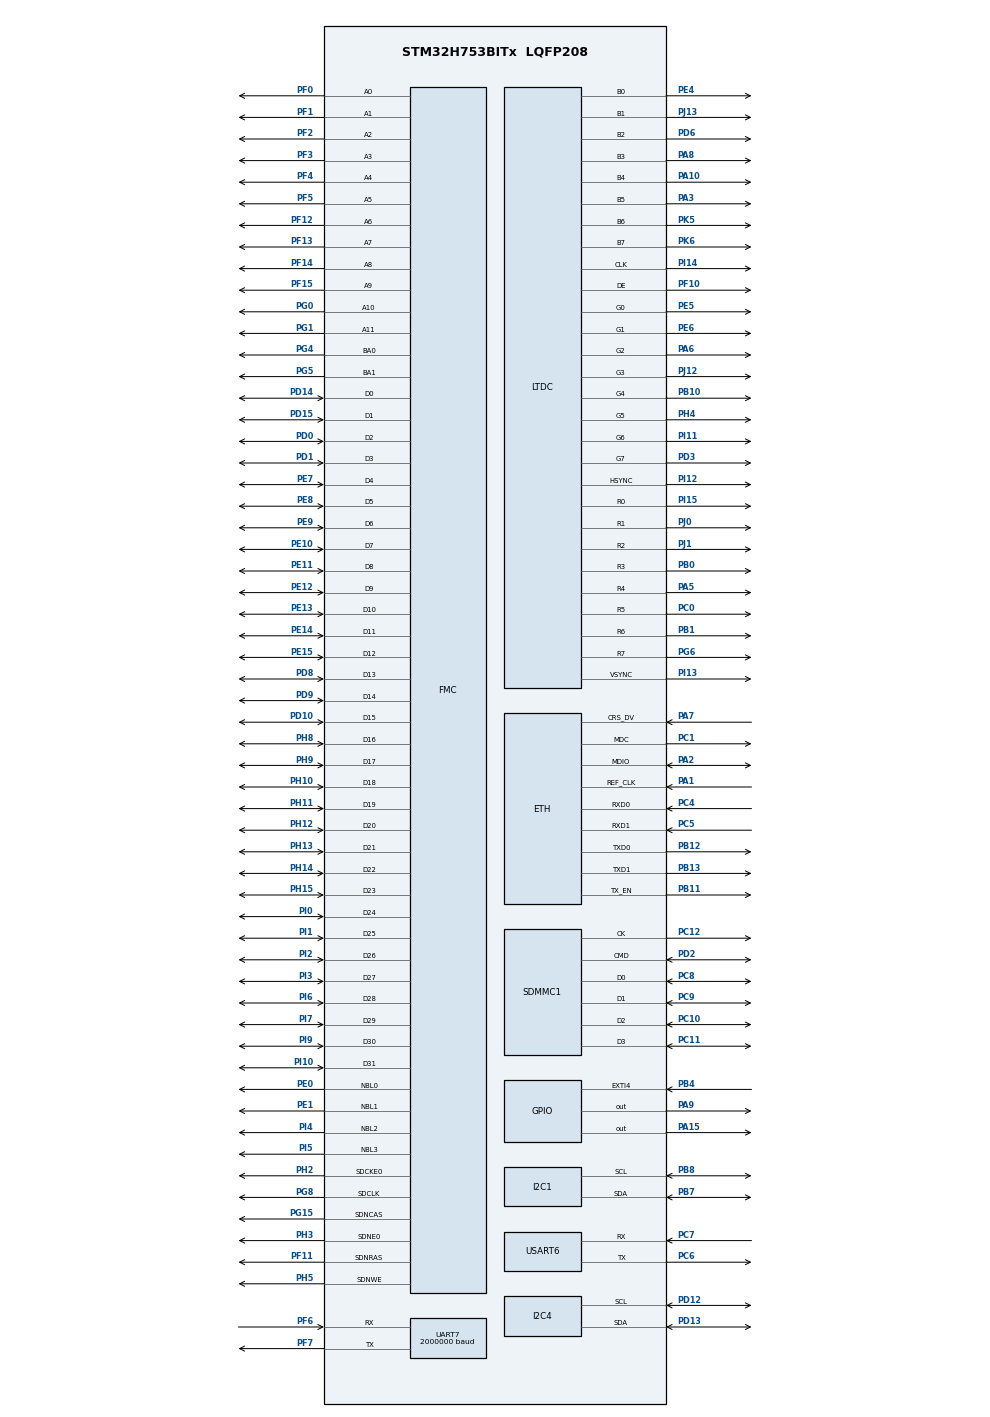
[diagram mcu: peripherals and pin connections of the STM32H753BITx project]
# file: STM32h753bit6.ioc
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CORTEX_M7.AccessPermission-Cortex_Memory_Protection_Unit_Region5_Settings=MPU_REGION_FULL_ACCESS
CORTEX_M7.AccessPermission-Cortex_Memory_Protection_Unit_Region6_Settings=MPU_REGION_FULL_ACCESS
CORTEX_M7.AccessPermission_S-Cortex_Memory_Protection_Unit_Region1_Settings_S=MPU_REGION_FULL_ACCESS
CORTEX_M7.AccessPermission_S-Cortex_Memory_Protection_Unit_Region2_Settings_S=MPU_REGION_FULL_ACCESS
CORTEX_M7.AccessPermission_S-Cortex_Memory_Protection_Unit_Region3_Settings_S=MPU_REGION_FULL_ACCESS
CORTEX_M7.AccessPermission_S-Cortex_Memory_Protection_Unit_Region4_Settings_S=MPU_REGION_FULL_ACCESS
CORTEX_M7.BaseAddress-Cortex_Memory_Protection_Unit_Region5_Settings=0x30040000
CORTEX_M7.BaseAddress-Cortex_Memory_Protection_Unit_Region6_Settings=0x30040000
CORTEX_M7.BaseAddress_S-Cortex_Memory_Protection_Unit_Region1_Settings_S=0x24000000
CORTEX_M7.BaseAddress_S-Cortex_Memory_Protection_Unit_Region2_Settings_S=0x30000000
CORTEX_M7.BaseAddress_S-Cortex_Memory_Protection_Unit_Region3_Settings_S=0x38000000
CORTEX_M7.BaseAddress_S-Cortex_Memory_Protection_Unit_Region4_Settings_S=0x60000000
CORTEX_M7.CPU_DCache=Enabled
CORTEX_M7.CPU_ICache=Enabled
CORTEX_M7.DisableExec-Cortex_Memory_Protection_Unit_Region5_Settings=MPU_INSTRUCTION_ACCESS_DISABLE
CORTEX_M7.DisableExec-Cortex_Memory_Protection_Unit_Region6_Settings=MPU_INSTRUCTION_ACCESS_DISABLE
CORTEX_M7.DisableExec_S-Cortex_Memory_Protection_Unit_Region1_Settings_S=MPU_INSTRUCTION_ACCESS_DISABLE
CORTEX_M7.DisableExec_S-Cortex_Memory_Protection_Unit_Region2_Settings_S=MPU_INSTRUCTION_ACCESS_DISABLE
CORTEX_M7.DisableExec_S-Cortex_Memory_Protection_Unit_Region3_Settings_S=MPU_INSTRUCTION_ACCESS_DISABLE
CORTEX_M7.DisableExec_S-Cortex_Memory_Protection_Unit_Region4_Settings_S=MPU_INSTRUCTION_ACCESS_DISABLE
CORTEX_M7.Enable-Cortex_Memory_Protection_Unit_Region5_Settings=MPU_REGION_ENABLE
CORTEX_M7.Enable-Cortex_Memory_Protection_Unit_Region6_Settings=MPU_REGION_ENABLE
CORTEX_M7.Enable_S-Cortex_Memory_Protection_Unit_Region1_Settings_S=MPU_REGION_ENABLE
CORTEX_M7.Enable_S-Cortex_Memory_Protection_Unit_Region2_Settings_S=MPU_REGION_ENABLE
CORTEX_M7.Enable_S-Cortex_Memory_Protection_Unit_Region3_Settings_S=MPU_REGION_ENABLE
CORTEX_M7.Enable_S-Cortex_Memory_Protection_Unit_Region4_Settings_S=MPU_REGION_ENABLE
CORTEX_M7.IsBufferable-Cortex_Memory_Protection_Unit_Region5_Settings=MPU_ACCESS_NOT_BUFFERABLE
CORTEX_M7.IsBufferable-Cortex_Memory_Protection_Unit_Region6_Settings=MPU_ACCESS_BUFFERABLE
CORTEX_M7.IsBufferable_S-Cortex_Memory_Protection_Unit_Region1_Settings_S=MPU_ACCESS_BUFFERABLE
CORTEX_M7.IsBufferable_S-Cortex_Memory_Protection_Unit_Region2_Settings_S=MPU_ACCESS_BUFFERABLE
CORTEX_M7.IsBufferable_S-Cortex_Memory_Protection_Unit_Region3_Settings_S=MPU_ACCESS_BUFFERABLE
CORTEX_M7.IsBufferable_S-Cortex_Memory_Protection_Unit_Region4_Settings_S=MPU_ACCESS_BUFFERABLE
CORTEX_M7.IsCacheable-Cortex_Memory_Protection_Unit_Region5_Settings=MPU_ACCESS_NOT_CACHEABLE
CORTEX_M7.IsCacheable-Cortex_Memory_Protection_Unit_Region6_Settings=MPU_ACCESS_NOT_CACHEABLE
CORTEX_M7.IsCacheable_S-Cortex_Memory_Protection_Unit_Region1_Settings_S=MPU_ACCESS_CACHEABLE
CORTEX_M7.IsCacheable_S-Cortex_Memory_Protection_Unit_Region2_Settings_S=MPU_ACCESS_CACHEABLE
CORTEX_M7.IsCacheable_S-Cortex_Memory_Protection_Unit_Region3_Settings_S=MPU_ACCESS_CACHEABLE
CORTEX_M7.IsCacheable_S-Cortex_Memory_Protection_Unit_Region4_Settings_S=MPU_ACCESS_CACHEABLE
CORTEX_M7.IsShareable-Cortex_Memory_Protection_Unit_Region6_Settings=MPU_ACCESS_SHAREABLE
CORTEX_M7.Size-Cortex_Memory_Protection_Unit_Region5_Settings=MPU_REGION_SIZE_32KB
CORTEX_M7.Size-Cortex_Memory_Protection_Unit_Region6_Settings=MPU_REGION_SIZE_256B
CORTEX_M7.Size_S-Cortex_Memory_Protection_Unit_Region1_Settings_S=MPU_REGION_SIZE_512KB
CORTEX_M7.Size_S-Cortex_Memory_Protection_Unit_Region2_Settings_S=MPU_REGION_SIZE_256KB
CORTEX_M7.Size_S-Cortex_Memory_Protection_Unit_Region3_Settings_S=MPU_REGION_SIZE_64KB
CORTEX_M7.Size_S-Cortex_Memory_Protection_Unit_Region4_Settings_S=MPU_REGION_SIZE_16MB
CORTEX_M7.TypeExtField-Cortex_Memory_Protection_Unit_Region5_Settings=MPU_TEX_LEVEL1
CORTEX_M7.TypeExtField_S-Cortex_Memory_Protection_Unit_Region1_Settings_S=MPU_TEX_LEVEL1
CORTEX_M7.TypeExtField_S-Cortex_Memory_Protection_Unit_Region2_Settings_S=MPU_TEX_LEVEL1
CORTEX_M7.TypeExtField_S-Cortex_Memory_Protection_Unit_Region3_Settings_S=MPU_TEX_LEVEL1
CORTEX_M7.TypeExtField_S-Cortex_Memory_Protection_Unit_Region4_Settings_S=MPU_TEX_LEVEL1
CORTEX_M7.default_mode_Activation=1
Dma.Request0=USART6_RX
Dma.Request1=USART6_TX
Dma.Request2=UART7_RX
Dma.Request3=UART7_TX
Dma.UART7_RX.2.Direction=DMA_PERIPH_TO_MEMORY
Dma.UART7_RX.2.EventEnable=DISABLE
Dma.UART7_RX.2.FIFOMode=DMA_FIFOMODE_DISABLE
Dma.UART7_RX.2.Instance=DMA1_Stream2
Dma.UART7_RX.2.MemDataAlignment=DMA_MDATAALIGN_BYTE
Dma.UART7_RX.2.MemInc=DMA_MINC_ENABLE
Dma.UART7_RX.2.Mode=DMA_NORMAL
Dma.UART7_RX.2.PeriphDataAlignment=DMA_PDATAALIGN_BYTE
Dma.UART7_RX.2.PeriphInc=DMA_PINC_DISABLE
Dma.UART7_RX.2.Polarity=HAL_DMAMUX_REQ_GEN_RISING
Dma.UART7_RX.2.Priority=DMA_PRIORITY_LOW
Dma.UART7_RX.2.RequestNumber=1
Dma.UART7_RX.2.SignalID=NONE
Dma.UART7_RX.2.SyncEnable=DISABLE
Dma.UART7_RX.2.SyncPolarity=HAL_DMAMUX_SYNC_NO_EVENT
Dma.UART7_RX.2.SyncRequestNumber=1
Dma.UART7_RX.2.SyncSignalID=NONE
Dma.UART7_TX.3.Direction=DMA_MEMORY_TO_PERIPH
Dma.UART7_TX.3.EventEnable=DISABLE
Dma.UART7_TX.3.FIFOMode=DMA_FIFOMODE_DISABLE
Dma.UART7_TX.3.Instance=DMA1_Stream3
Dma.UART7_TX.3.MemDataAlignment=DMA_MDATAALIGN_BYTE
Dma.UART7_TX.3.MemInc=DMA_MINC_ENABLE
Dma.UART7_TX.3.Mode=DMA_NORMAL
Dma.UART7_TX.3.PeriphDataAlignment=DMA_PDATAALIGN_BYTE
Dma.UART7_TX.3.PeriphInc=DMA_PINC_DISABLE
Dma.UART7_TX.3.Polarity=HAL_DMAMUX_REQ_GEN_RISING
Dma.UART7_TX.3.Priority=DMA_PRIORITY_LOW
Dma.UART7_TX.3.RequestNumber=1
Dma.UART7_TX.3.SignalID=NONE
Dma.UART7_TX.3.SyncEnable=DISABLE
Dma.UART7_TX.3.SyncPolarity=HAL_DMAMUX_SYNC_NO_EVENT
Dma.UART7_TX.3.SyncRequestNumber=1
Dma.UART7_TX.3.SyncSignalID=NONE
Dma.USART6_RX.0.Direction=DMA_PERIPH_TO_MEMORY
Dma.USART6_RX.0.EventEnable=DISABLE
Dma.USART6_RX.0.FIFOMode=DMA_FIFOMODE_DISABLE
Dma.USART6_RX.0.Instance=DMA1_Stream0
Dma.USART6_RX.0.MemDataAlignment=DMA_MDATAALIGN_BYTE
Dma.USART6_RX.0.MemInc=DMA_MINC_ENABLE
Dma.USART6_RX.0.Mode=DMA_CIRCULAR
Dma.USART6_RX.0.PeriphDataAlignment=DMA_PDATAALIGN_BYTE
Dma.USART6_RX.0.PeriphInc=DMA_PINC_DISABLE
Dma.USART6_RX.0.Polarity=HAL_DMAMUX_REQ_GEN_RISING
Dma.USART6_RX.0.Priority=DMA_PRIORITY_LOW
Dma.USART6_RX.0.RequestNumber=1
Dma.USART6_RX.0.SignalID=NONE
Dma.USART6_RX.0.SyncEnable=DISABLE
Dma.USART6_RX.0.SyncPolarity=HAL_DMAMUX_SYNC_NO_EVENT
Dma.USART6_RX.0.SyncRequestNumber=1
Dma.USART6_RX.0.SyncSignalID=NONE
Dma.USART6_TX.1.Direction=DMA_MEMORY_TO_PERIPH
Dma.USART6_TX.1.EventEnable=DISABLE
Dma.USART6_TX.1.FIFOMode=DMA_FIFOMODE_DISABLE
Dma.USART6_TX.1.Instance=DMA1_Stream1
Dma.USART6_TX.1.MemDataAlignment=DMA_MDATAALIGN_BYTE
Dma.USART6_TX.1.MemInc=DMA_MINC_ENABLE
Dma.USART6_TX.1.Mode=DMA_NORMAL
Dma.USART6_TX.1.PeriphDataAlignment=DMA_PDATAALIGN_BYTE
Dma.USART6_TX.1.PeriphInc=DMA_PINC_DISABLE
Dma.USART6_TX.1.Polarity=HAL_DMAMUX_REQ_GEN_RISING
Dma.USART6_TX.1.Priority=DMA_PRIORITY_LOW
Dma.USART6_TX.1.RequestNumber=1
Dma.USART6_TX.1.SignalID=NONE
Dma.USART6_TX.1.SyncEnable=DISABLE
Dma.USART6_TX.1.SyncPolarity=HAL_DMAMUX_SYNC_NO_EVENT
Dma.USART6_TX.1.SyncRequestNumber=1
Dma.USART6_TX.1.SyncSignalID=NONE
ETH.MediaInterface=HAL_ETH_RMII_MODE
ETH.RxBuffAddress=0x30040200
ETH.RxBuffLen=1536
FATFS.USE_DMA_CODE_SD=1
FATFS._CODE_PAGE=775
FATFS._FS_LOCK=10
FATFS._FS_RPATH=2
FATFS._FS_TIMEOUT=2000
FATFS._USE_CHMOD=1
FATFS._USE_EXPAND=1
FATFS._USE_FIND=1
FATFS._USE_LFN=3
FMC.BankMapConfig=FMC_SWAPBMAP_SDRAM_SRAM
FMC.CASLatency1=FMC_SDRAM_CAS_LATENCY_2
FMC.ExitSelfRefreshDelay1=7
FMC.LoadToActiveDelay1=2
FMC.RCDDelay1=2
FMC.RPDelay1=2
FMC.RPDelay2=2
FMC.ReadBurst1=FMC_SDRAM_RBURST_ENABLE
FMC.ReadBurst2=FMC_SDRAM_RBURST_ENABLE
FMC.ReadPipeDelay1=FMC_SDRAM_RPIPE_DELAY_1
FMC.ReadPipeDelay2=FMC_SDRAM_RPIPE_DELAY_1
FMC.RowCycleDelay1=7
FMC.RowCycleDelay2=7
FMC.SDClockPeriod1=FMC_SDRAM_CLOCK_PERIOD_2
FMC.SDClockPeriod2=FMC_SDRAM_CLOCK_PERIOD_2
FMC.SelfRefreshTime1=5
FMC.WriteRecoveryTime1=3
FREERTOS.INCLUDE_vTaskDelayUntil=1
FREERTOS.INCLUDE_xEventGroupSetBitFromISR=1
FREERTOS.INCLUDE_xTimerPendFunctionCall=1
FREERTOS.Tasks01=defaultTask,0,2048,StartDefaultTask,Default,NULL,Dynamic,NULL,NULL
FREERTOS.configENABLE_FPU=1
FREERTOS.configMAX_PRIORITIES=9
FREERTOS.configMINIMAL_STACK_SIZE=256
FREERTOS.configTOTAL_HEAP_SIZE=131072
FREERTOS.configUSE_IDLE_HOOK=1
FREERTOS.configUSE_TICK_HOOK=1
FREERTOS.configUSE_TIMERS=1
FREERTOS.configUSE_TRACE_FACILITY=1
I2C1.Timing=0x307075B1
I2C4.Timing=0x307075B1
LTDC.ActiveW=800
LTDC.Alpha0_L0=255
LTDC.Alpha_L0=255
LTDC.BlendingFactor1_L0=LTDC_BLENDING_FACTOR1_PAxCA
LTDC.BlendingFactor2_L0=LTDC_BLENDING_FACTOR2_PAxCA
LTDC.FBStartAdress_L0=0x60000000
LTDC.HSync=39
LTDC.ImageHeight_L0=480
LTDC.ImageWidth_L0=800
LTDC.Layers=0
LTDC.PixelFormat_L0=LTDC_PIXEL_FORMAT_RGB888
LTDC.VSync=3
LTDC.WindowX1_L0=800
LTDC.WindowY1_L0=480
LWIP.BSP.number=1
LWIP.DEFAULT_THREAD_STACKSIZE=8000
LWIP.GATEWAY_ADDRESS=192.168.001.001
LWIP.IP_ADDRESS=192.168.001.040
LWIP.LWIP_DHCP=0
LWIP.LWIP_DNS=1
LWIP.LWIP_RAM_HEAP_POINTER=0x30044000
LWIP.LWIP_SMTP=1
LWIP.LWIP_SNTP=1
LWIP.LWIP_TCPIP_CORE_LOCKING=1
LWIP.MEMP_NUM_NETBUF=32
LWIP.MEMP_NUM_NETCONN=32
LWIP.MEMP_NUM_PBUF=32
LWIP.MEMP_NUM_SYS_TIMEOUT=32
LWIP.MEMP_NUM_TCP_SEG=32
LWIP.MEM_ALIGNMENT=4
LWIP.MEM_SIZE=16360
LWIP.NETMASK_ADDRESS=255.255.255.000
LWIP.PBUF_POOL_BUFSIZE=1526
LWIP.PBUF_POOL_SIZE=24
LWIP.SLIPIF_THREAD_STACKSIZE=16000
LWIP.SO_REUSE=1
LWIP.TCP_MSS=1460
LWIP.TCP_SNDLOWAT=2919
LWIP.TCP_SND_BUF=2920
LWIP.TCP_WND_UPDATE_THRESHOLD=1460
LWIP.Version=v2.1.2_Cube
LWIP0.BSP.STBoard=false
LWIP0.BSP.api=BSP_COMPONENT_DRIVER
LWIP0.BSP.component=LAN8742
LWIP0.BSP.instance=LAN8742
LWIP0.BSP.name=Driver_PHY
LWIP0.BSP.semaphore=S_LAN8742
LWIP0.BSP.solution=LAN8742
MBEDTLS.MBEDTLS_KEY_EXCHANGE_ECDH_RSA_ENABLED=1
MBEDTLS.MBEDTLS_MEMORY_BUFFER_ALLOC_C=1
MBEDTLS.MBEDTLS_PK_RSA_ALT_SUPPORT=0
MBEDTLS.MBEDTLS_PLATFORM_MEMORY=1
MBEDTLS.MBEDTLS_RSA_C=1
MBEDTLS.MBEDTLS_THREADING_C=1
MBEDTLS.MBEDTLS_X509_RSASSA_PSS_SUPPORT=1
Mcu.Family=STM32H7
Mcu.Name=STM32H753BITx
Mcu.Package=LQFP208
Mdma.MDMA_Channel0.Request0=SDMMC1_END_DATA
Mdma.MDMA_Channel0.RequestsNb=1
Mdma.MDMA_Channel0.SDMMC1_END_DATA.0.BlockCount=0
Mdma.MDMA_Channel0.SDMMC1_END_DATA.0.BlockDataLength=0
Mdma.MDMA_Channel0.SDMMC1_END_DATA.0.BufferTransferLength=16
Mdma.MDMA_Channel0.SDMMC1_END_DATA.0.CircularMode=MDMA_LINEAR_LIST
Mdma.MDMA_Channel0.SDMMC1_END_DATA.0.DataAlignment=MDMA_DATAALIGN_PACKENABLE
Mdma.MDMA_Channel0.SDMMC1_END_DATA.0.DestBlockAddressOffset=0
Mdma.MDMA_Channel0.SDMMC1_END_DATA.0.DestBurst=MDMA_DEST_BURST_SINGLE
Mdma.MDMA_Channel0.SDMMC1_END_DATA.0.DestDataSize=MDMA_DEST_DATASIZE_BYTE
Mdma.MDMA_Channel0.SDMMC1_END_DATA.0.DestinationInc=MDMA_DEST_INC_BYTE
Mdma.MDMA_Channel0.SDMMC1_END_DATA.0.DstAddress=0
Mdma.MDMA_Channel0.SDMMC1_END_DATA.0.Endianness=MDMA_LITTLE_ENDIANNESS_PRESERVE
Mdma.MDMA_Channel0.SDMMC1_END_DATA.0.Instance=MDMA_Channel0
Mdma.MDMA_Channel0.SDMMC1_END_DATA.0.MaskAddress=0
Mdma.MDMA_Channel0.SDMMC1_END_DATA.0.MaskData=0
Mdma.MDMA_Channel0.SDMMC1_END_DATA.0.Priority=MDMA_PRIORITY_LOW
Mdma.MDMA_Channel0.SDMMC1_END_DATA.0.Rank=First
Mdma.MDMA_Channel0.SDMMC1_END_DATA.0.SourceBlockAddressOffset=0
Mdma.MDMA_Channel0.SDMMC1_END_DATA.0.SourceBurst=MDMA_SOURCE_BURST_SINGLE
Mdma.MDMA_Channel0.SDMMC1_END_DATA.0.SourceDataSize=MDMA_SRC_DATASIZE_BYTE
Mdma.MDMA_Channel0.SDMMC1_END_DATA.0.SourceInc=MDMA_SRC_INC_BYTE
Mdma.MDMA_Channel0.SDMMC1_END_DATA.0.SrcAddress=0
Mdma.MDMA_Channel0.SDMMC1_END_DATA.0.TransferTriggerMode=MDMA_BUFFER_TRANSFER
Mdma.RequestSet0=MDMA_Channel0
Mdma.RequestSetsNb=1
NVIC.DMA1_Stream0_IRQn=true\:5\:0\:false\:false\:true\:true\:false\:true\:true
NVIC.DMA1_Stream1_IRQn=true\:5\:0\:false\:false\:true\:true\:false\:true\:true
NVIC.DMA1_Stream2_IRQn=true\:5\:0\:false\:false\:true\:true\:false\:true\:true
NVIC.DMA1_Stream3_IRQn=true\:5\:0\:false\:false\:true\:true\:false\:true\:true
NVIC.ETH_IRQn=true\:5\:0\:false\:false\:true\:true\:true\:true\:true
NVIC.EXTI4_IRQn=true\:5\:0\:false\:false\:true\:true\:true\:true\:true
NVIC.MDMA_IRQn=true\:5\:0\:false\:false\:true\:true\:false\:true\:true
NVIC.PriorityGroup=NVIC_PRIORITYGROUP_4
NVIC.SDMMC1_IRQn=true\:5\:0\:false\:false\:true\:true\:true\:true\:true
NVIC.TIM8_TRG_COM_TIM14_IRQn=true\:15\:0\:false\:false\:true\:false\:false\:true\:true
NVIC.TimeBase=TIM8_TRG_COM_TIM14_IRQn
NVIC.TimeBaseIP=TIM14
NVIC.UART7_IRQn=true\:5\:0\:false\:false\:true\:true\:true\:true\:true
NVIC.USART6_IRQn=true\:5\:0\:false\:false\:true\:true\:true\:true\:true
PA1.Mode=RMII
PA1.Signal=ETH_REF_CLK
PA10.Mode=RGB888
PA10.Signal=LTDC_B4
PA13\ (JTMS/SWDIO).Mode=Serial_Wire
PA13\ (JTMS/SWDIO).Signal=DEBUG_JTMS-SWDIO
PA14\ (JTCK/SWCLK).Mode=Serial_Wire
PA14\ (JTCK/SWCLK).Signal=DEBUG_JTCK-SWCLK
PA15\ (JTDI).Signal=GPIO_Output
PA2.Mode=RMII
PA2.Signal=ETH_MDIO
PA3.Mode=RGB888
PA3.Signal=LTDC_B5
PA5.Mode=RGB888
PA5.Signal=LTDC_R4
PA6.Mode=RGB888
PA6.Signal=LTDC_G2
PA7.Mode=RMII
PA7.Signal=ETH_CRS_DV
PA8.Mode=RGB888
PA8.Signal=LTDC_B3
PA9.Signal=GPIO_Output
PB0.Mode=RGB888
PB0.Signal=LTDC_R3
PB1.Mode=RGB888
PB1.Signal=LTDC_R6
PB10.Mode=RGB888
PB10.Signal=LTDC_G4
PB11.Mode=RMII
PB11.Signal=ETH_TX_EN
PB12.Mode=RMII
PB12.Signal=ETH_TXD0
PB13.Mode=RMII
PB13.Signal=ETH_TXD1
PB4\ (NJTRST).GPIO_ModeDefaultEXTI=GPIO_MODE_IT_RISING_FALLING
PB4\ (NJTRST).GPIO_PuPd=GPIO_PULLUP
PB4\ (NJTRST).Signal=GPXTI4
PB7.Mode=I2C
PB7.Signal=I2C1_SDA
PB8.Mode=I2C
PB8.Signal=I2C1_SCL
PC0.Mode=RGB888
PC0.Signal=LTDC_R5
PC1.Mode=RMII
PC1.Signal=ETH_MDC
PC10.Mode=SD_4_bits_Wide_bus
PC10.Signal=SDMMC1_D2
PC11.Mode=SD_4_bits_Wide_bus
PC11.Signal=SDMMC1_D3
PC12.Mode=SD_4_bits_Wide_bus
PC12.Signal=SDMMC1_CK
PC4.Mode=RMII
PC4.Signal=ETH_RXD0
PC5.Mode=RMII
PC5.Signal=ETH_RXD1
PC6.GPIO_Speed=GPIO_SPEED_FREQ_HIGH
PC6.Mode=Asynchronous
PC6.Signal=USART6_TX
PC7.GPIO_PuPd=GPIO_PULLUP
PC7.GPIO_Speed=GPIO_SPEED_FREQ_HIGH
PC7.Mode=Asynchronous
PC7.Signal=USART6_RX
PC8.Mode=SD_4_bits_Wide_bus
PC8.Signal=SDMMC1_D0
PC9.Mode=SD_4_bits_Wide_bus
PC9.Signal=SDMMC1_D1
PD0.Signal=FMC_D2_DA2
PD1.Signal=FMC_D3_DA3
PD10.Signal=FMC_D15_DA15
PD12.Mode=I2C
PD12.Signal=I2C4_SCL
PD13.Mode=I2C
PD13.Signal=I2C4_SDA
PD14.Signal=FMC_D0_DA0
PD15.Signal=FMC_D1_DA1
PD2.Mode=SD_4_bits_Wide_bus
PD2.Signal=SDMMC1_CMD
PD3.Mode=RGB888
PD3.Signal=LTDC_G7
PD6.Mode=RGB888
PD6.Signal=LTDC_B2
PD8.Signal=FMC_D13_DA13
PD9.Signal=FMC_D14_DA14
PE0.Signal=FMC_NBL0
PE1.Signal=FMC_NBL1
PE10.Signal=FMC_D7_DA7
PE11.Signal=FMC_D8_DA8
PE12.Signal=FMC_D9_DA9
PE13.Signal=FMC_D10_DA10
PE14.Signal=FMC_D11_DA11
PE15.Signal=FMC_D12_DA12
PE4.Mode=RGB888
PE4.Signal=LTDC_B0
PE5.Mode=RGB888
PE5.Signal=LTDC_G0
PE6.Mode=RGB888
PE6.Signal=LTDC_G1
PE7.Signal=FMC_D4_DA4
PE8.Signal=FMC_D5_DA5
PE9.Signal=FMC_D6_DA6
PF0.Signal=FMC_A0
PF1.Signal=FMC_A1
PF10.Mode=RGB888
PF10.Signal=LTDC_DE
PF11.Signal=FMC_SDNRAS
PF12.Signal=FMC_A6
PF13.Signal=FMC_A7
PF14.Signal=FMC_A8
PF15.Signal=FMC_A9
PF2.Signal=FMC_A2
PF3.Signal=FMC_A3
PF4.Signal=FMC_A4
PF5.Signal=FMC_A5
PF6.GPIO_PuPd=GPIO_PULLUP
PF6.Mode=Asynchronous
PF6.Signal=UART7_RX
PF7.Mode=Asynchronous
PF7.Signal=UART7_TX
PG0.Signal=FMC_A10
PG1.Signal=FMC_A11
PG15.Signal=FMC_SDNCAS
PG4.Signal=FMC_A14_BA0
PG5.Signal=FMC_A15_BA1
PG6.Mode=RGB888
PG6.Signal=LTDC_R7
PG8.Signal=FMC_SDCLK
PH0-OSC_IN\ (PH0).Mode=HSE-External-Oscillator
PH0-OSC_IN\ (PH0).Signal=RCC_OSC_IN
PH1-OSC_OUT\ (PH1).Mode=HSE-External-Oscillator
PH1-OSC_OUT\ (PH1).Signal=RCC_OSC_OUT
PH10.Signal=FMC_D18
PH11.Signal=FMC_D19
PH12.Signal=FMC_D20
PH13.Signal=FMC_D21
PH14.Signal=FMC_D22
PH15.Signal=FMC_D23
PH2.Mode=SdramChipSelect1_1
PH2.Signal=FMC_SDCKE0
PH3.Mode=SdramChipSelect1_1
PH3.Signal=FMC_SDNE0
PH4.Mode=RGB888
PH4.Signal=LTDC_G5
PH5.Signal=FMC_SDNWE
PH8.Signal=FMC_D16
PH9.Signal=FMC_D17
PI0.Signal=FMC_D24
PI1.Signal=FMC_D25
PI10.Signal=FMC_D31
PI11.Mode=RGB888
PI11.Signal=LTDC_G6
PI12.Mode=RGB888
PI12.Signal=LTDC_HSYNC
PI13.Mode=RGB888
PI13.Signal=LTDC_VSYNC
PI14.Mode=RGB888
PI14.Signal=LTDC_CLK
PI15.Mode=RGB888
PI15.Signal=LTDC_R0
PI2.Signal=FMC_D26
PI3.Signal=FMC_D27
PI4.Signal=FMC_NBL2
PI5.Signal=FMC_NBL3
PI6.Signal=FMC_D28
PI7.Signal=FMC_D29
PI9.Signal=FMC_D30
PJ0.Mode=RGB888
PJ0.Signal=LTDC_R1
PJ1.Mode=RGB888
PJ1.Signal=LTDC_R2
PJ12.Mode=RGB888
PJ12.Signal=LTDC_G3
PJ13.Mode=RGB888
PJ13.Signal=LTDC_B1
PK5.Mode=RGB888
PK5.Signal=LTDC_B6
PK6.Mode=RGB888
PK6.Signal=LTDC_B7
ProjectManager.HeapSize=0x4000
ProjectManager.StackSize=0x4000
ProjectManager.TargetToolchain=STM32CubeIDE
RCC.ADCFreq_Value=100000000
RCC.APB1Freq_Value=120000000
RCC.APB2Freq_Value=120000000
RCC.APB3Freq_Value=120000000
RCC.APB4Freq_Value=120000000
RCC.CortexFreq_Value=480000000
RCC.D1PPRE=RCC_APB3_DIV2
RCC.D2PPRE1=RCC_APB1_DIV2
RCC.D2PPRE2=RCC_APB2_DIV2
RCC.D3PPRE=RCC_APB4_DIV2
RCC.DIVM1=5
RCC.DIVM2=5
RCC.DIVM3=1
RCC.DIVN1=192
RCC.DIVN2=40
RCC.DIVN3=23
RCC.DIVQ1=20
RCC.DIVQ2=5
RCC.DIVQ3=5
RCC.DIVR2=1
RCC.DIVR3=25
RCC.FMCCLockSelection=RCC_FMCCLKSOURCE_PLL2
RCC.HCLKFreq_Value=240000000
RCC.HPRE=RCC_HCLK_DIV2
RCC.PLL2FRACN=0
RCC.PLL3FRACN=0
RCC.PLLFRACN=0
RCC.PLLSourceVirtual=RCC_PLLSOURCE_HSE
RCC.SYSCLKFreq_VALUE=480000000
RCC.SYSCLKSource=RCC_SYSCLKSOURCE_PLLCLK
RCC.USBFreq_Value=48000000
SH.FMC_A0.0=FMC_A0,12b-sda1
SH.FMC_A1.0=FMC_A1,12b-sda1
SH.FMC_A10.0=FMC_A10,12b-sda1
SH.FMC_A11.0=FMC_A11,12b-sda1
SH.FMC_A14_BA0.0=FMC_BA0,FourSdramBanks1
SH.FMC_A15_BA1.0=FMC_BA1,FourSdramBanks1
SH.FMC_A2.0=FMC_A2,12b-sda1
SH.FMC_A3.0=FMC_A3,12b-sda1
SH.FMC_A4.0=FMC_A4,12b-sda1
SH.FMC_A5.0=FMC_A5,12b-sda1
SH.FMC_A6.0=FMC_A6,12b-sda1
SH.FMC_A7.0=FMC_A7,12b-sda1
SH.FMC_A8.0=FMC_A8,12b-sda1
SH.FMC_A9.0=FMC_A9,12b-sda1
SH.FMC_D0_DA0.0=FMC_D0,sd-32b-d1
SH.FMC_D10_DA10.0=FMC_D10,sd-32b-d1
SH.FMC_D11_DA11.0=FMC_D11,sd-32b-d1
SH.FMC_D12_DA12.0=FMC_D12,sd-32b-d1
SH.FMC_D13_DA13.0=FMC_D13,sd-32b-d1
SH.FMC_D14_DA14.0=FMC_D14,sd-32b-d1
SH.FMC_D15_DA15.0=FMC_D15,sd-32b-d1
SH.FMC_D16.0=FMC_D16,sd-32b-d1
SH.FMC_D17.0=FMC_D17,sd-32b-d1
SH.FMC_D18.0=FMC_D18,sd-32b-d1
SH.FMC_D19.0=FMC_D19,sd-32b-d1
SH.FMC_D1_DA1.0=FMC_D1,sd-32b-d1
SH.FMC_D20.0=FMC_D20,sd-32b-d1
SH.FMC_D21.0=FMC_D21,sd-32b-d1
SH.FMC_D22.0=FMC_D22,sd-32b-d1
SH.FMC_D23.0=FMC_D23,sd-32b-d1
SH.FMC_D24.0=FMC_D24,sd-32b-d1
SH.FMC_D25.0=FMC_D25,sd-32b-d1
SH.FMC_D26.0=FMC_D26,sd-32b-d1
SH.FMC_D27.0=FMC_D27,sd-32b-d1
SH.FMC_D28.0=FMC_D28,sd-32b-d1
SH.FMC_D29.0=FMC_D29,sd-32b-d1
SH.FMC_D2_DA2.0=FMC_D2,sd-32b-d1
SH.FMC_D30.0=FMC_D30,sd-32b-d1
SH.FMC_D31.0=FMC_D31,sd-32b-d1
SH.FMC_D3_DA3.0=FMC_D3,sd-32b-d1
SH.FMC_D4_DA4.0=FMC_D4,sd-32b-d1
SH.FMC_D5_DA5.0=FMC_D5,sd-32b-d1
SH.FMC_D6_DA6.0=FMC_D6,sd-32b-d1
SH.FMC_D7_DA7.0=FMC_D7,sd-32b-d1
SH.FMC_D8_DA8.0=FMC_D8,sd-32b-d1
SH.FMC_D9_DA9.0=FMC_D9,sd-32b-d1
SH.FMC_NBL0.0=FMC_NBL0,Sd4ByteEnable1
SH.FMC_NBL1.0=FMC_NBL1,Sd4ByteEnable1
SH.FMC_NBL2.0=FMC_NBL2,Sd4ByteEnable1
SH.FMC_NBL3.0=FMC_NBL3,Sd4ByteEnable1
SH.FMC_SDCLK.0=FMC_SDCLK,12b-sda1
SH.FMC_SDNCAS.0=FMC_SDNCAS,12b-sda1
SH.FMC_SDNRAS.0=FMC_SDNRAS,12b-sda1
SH.FMC_SDNWE.0=FMC_SDNWE,12b-sda1
TIM5.CounterMode=TIM_COUNTERMODE_UP
UART7.BaudRate=2000000
USART6.SwapParam=ADVFEATURE_SWAP_ENABLE
USART6.VirtualMode-Asynchronous=VM_ASYNC
VP_FATFS_VS_SDIO.Mode=SDIO
VP_FREERTOS_VS_CMSIS_V1.Mode=CMSIS_V1
VP_LWIP_VS_Enabled.Mode=Enabled
VP_MBEDTLS_VS_MBEDTLS.Mode=Enabled
VP_MEMORYMAP_VS_MEMORYMAP.Mode=CurAppReg
VP_RNG_VS_RNG.Mode=RNG_Activate
VP_SYS_VS_tim14.Mode=TIM14
VP_TIM5_VS_ClockSourceINT.Mode=Internal
board=custom

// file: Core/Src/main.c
/* USER CODE BEGIN Header */
/**
  ******************************************************************************
  * @file           : main.c
  * @brief          : Main program body
  ******************************************************************************
  * @attention
  *
  * Copyright (c) 2026 STMicroelectronics.
  * All rights reserved.
  *
  * This software is licensed under terms that can be found in the LICENSE file
  * in the root directory of this software component.
  * If no LICENSE file comes with this software, it is provided AS-IS.
  *
  ******************************************************************************
  */
/* USER CODE END Header */
#include "main.h"
#include "cmsis_os.h"
#include "dma.h"
#include "fatfs.h"
#include "i2c.h"
#include "ltdc.h"
#include "mbedtls.h"
#include "mdma.h"
#include "rng.h"
#include "sdmmc.h"
#include "tim.h"
#include "usart.h"
#include "gpio.h"
#include "fmc.h"

/* USER CODE BEGIN Includes */
#include "network_memory.h"
#include "relay_states.h"
/* USER CODE END Includes */

void SystemClock_Config(void);
static void MPU_Config(void);
void MX_FREERTOS_Init(void);

int main(void)
{

  /* USER CODE BEGIN 1 */
	/* The custom linker exports the application vector base for both variants. */
	extern const uint32_t __h753_app_vectors[];
	SCB->VTOR = (uint32_t) __h753_app_vectors;
	__DSB ();
	__ISB ();
	SCB_InvalidateICache ();
	SCB_InvalidateDCache ();
	/* USER CODE END 1 */

  /* MPU Configuration--------------------------------------------------------*/
  MPU_Config();

  /* Enable the CPU Cache */

  /* Enable I-Cache---------------------------------------------------------*/
  SCB_EnableICache();

  /* Enable D-Cache---------------------------------------------------------*/
  SCB_EnableDCache();

  /* MCU Configuration--------------------------------------------------------*/

  /* Reset of all peripherals, Initializes the Flash interface and the Systick. */
  HAL_Init();

  /* Configure the system clock */
  SystemClock_Config();

  /* USER CODE BEGIN SysInit */
	NetworkConfigureMemory ();

	/* USER CODE END SysInit */

  /* Initialize all configured peripherals */
  MX_GPIO_Init();
  MX_MDMA_Init();
  MX_DMA_Init();
  MX_SDMMC1_SD_Init();
  MX_FMC_Init();
  MX_I2C1_Init();
  MX_I2C4_Init();
  MX_UART7_Init();
  MX_USART6_UART_Init();
  MX_LTDC_Init();
  MX_TIM5_Init();
  MX_RNG_Init();
  /* Call PreOsInit function */
  MX_MBEDTLS_Init();
  /* USER CODE BEGIN 2 */
	RELAY_ResetStates ();
	/* USER CODE END 2 */

  /* Call init function for freertos objects (in cmsis_os2.c) */
  MX_FREERTOS_Init();

  /* Start scheduler */
  osKernelStart();

  /* We should never get here as control is now taken by the scheduler */

  /* Infinite loop */
	while ( 1 )
	{

	}
}

void SystemClock_Config(void)
{
  RCC_OscInitTypeDef RCC_OscInitStruct = {0};
  RCC_ClkInitTypeDef RCC_ClkInitStruct = {0};

  /** Supply configuration update enable
  */
  HAL_PWREx_ConfigSupply(PWR_LDO_SUPPLY);

  /** Configure the main internal regulator output voltage
  */
  __HAL_PWR_VOLTAGESCALING_CONFIG(PWR_REGULATOR_VOLTAGE_SCALE0);

  while(!__HAL_PWR_GET_FLAG(PWR_FLAG_VOSRDY)) {}

  /** Initializes the RCC Oscillators according to the specified parameters
  * in the RCC_OscInitTypeDef structure.
  */
  RCC_OscInitStruct.OscillatorType = RCC_OSCILLATORTYPE_HSI48|RCC_OSCILLATORTYPE_HSE;
  RCC_OscInitStruct.HSEState = RCC_HSE_ON;
  RCC_OscInitStruct.HSI48State = RCC_HSI48_ON;
  RCC_OscInitStruct.PLL.PLLState = RCC_PLL_ON;
  RCC_OscInitStruct.PLL.PLLSource = RCC_PLLSOURCE_HSE;
  RCC_OscInitStruct.PLL.PLLM = 5;
  RCC_OscInitStruct.PLL.PLLN = 192;
  RCC_OscInitStruct.PLL.PLLP = 2;
  RCC_OscInitStruct.PLL.PLLQ = 20;
  RCC_OscInitStruct.PLL.PLLR = 2;
  RCC_OscInitStruct.PLL.PLLRGE = RCC_PLL1VCIRANGE_2;
  RCC_OscInitStruct.PLL.PLLVCOSEL = RCC_PLL1VCOWIDE;
  RCC_OscInitStruct.PLL.PLLFRACN = 0;
  if (HAL_RCC_OscConfig(&RCC_OscInitStruct) != HAL_OK)
  {
    Error_Handler();
  }

  /** Initializes the CPU, AHB and APB buses clocks
  */
  RCC_ClkInitStruct.ClockType = RCC_CLOCKTYPE_HCLK|RCC_CLOCKTYPE_SYSCLK
                              |RCC_CLOCKTYPE_PCLK1|RCC_CLOCKTYPE_PCLK2
                              |RCC_CLOCKTYPE_D3PCLK1|RCC_CLOCKTYPE_D1PCLK1;
  RCC_ClkInitStruct.SYSCLKSource = RCC_SYSCLKSOURCE_PLLCLK;
  RCC_ClkInitStruct.SYSCLKDivider = RCC_SYSCLK_DIV1;
  RCC_ClkInitStruct.AHBCLKDivider = RCC_HCLK_DIV2;
  RCC_ClkInitStruct.APB3CLKDivider = RCC_APB3_DIV2;
  RCC_ClkInitStruct.APB1CLKDivider = RCC_APB1_DIV2;
  RCC_ClkInitStruct.APB2CLKDivider = RCC_APB2_DIV2;
  RCC_ClkInitStruct.APB4CLKDivider = RCC_APB4_DIV2;

  if (HAL_RCC_ClockConfig(&RCC_ClkInitStruct, FLASH_LATENCY_4) != HAL_OK)
  {
    Error_Handler();
  }
}

 /* MPU Configuration */

void MPU_Config(void)
{
  MPU_Region_InitTypeDef MPU_InitStruct = {0};

  /* Disables the MPU */
  HAL_MPU_Disable();

  /** Initializes and configures the Region and the memory to be protected
  */
  MPU_InitStruct.Enable = MPU_REGION_ENABLE;
  MPU_InitStruct.Number = MPU_REGION_NUMBER0;
  MPU_InitStruct.BaseAddress = 0x0;
  MPU_InitStruct.Size = MPU_REGION_SIZE_4GB;
  MPU_InitStruct.SubRegionDisable = 0x87;
  MPU_InitStruct.TypeExtField = MPU_TEX_LEVEL0;
  MPU_InitStruct.AccessPermission = MPU_REGION_NO_ACCESS;
  MPU_InitStruct.DisableExec = MPU_INSTRUCTION_ACCESS_DISABLE;
  MPU_InitStruct.IsShareable = MPU_ACCESS_SHAREABLE;
  MPU_InitStruct.IsCacheable = MPU_ACCESS_NOT_CACHEABLE;
  MPU_InitStruct.IsBufferable = MPU_ACCESS_NOT_BUFFERABLE;

  HAL_MPU_ConfigRegion(&MPU_InitStruct);

  /** Initializes and configures the Region and the memory to be protected
  */
  MPU_InitStruct.Number = MPU_REGION_NUMBER1;
  MPU_InitStruct.BaseAddress = 0x24000000;
  MPU_InitStruct.Size = MPU_REGION_SIZE_512KB;
  MPU_InitStruct.SubRegionDisable = 0x0;
  MPU_InitStruct.TypeExtField = MPU_TEX_LEVEL1;
  MPU_InitStruct.AccessPermission = MPU_REGION_FULL_ACCESS;
  MPU_InitStruct.IsShareable = MPU_ACCESS_NOT_SHAREABLE;
  MPU_InitStruct.IsCacheable = MPU_ACCESS_CACHEABLE;
  MPU_InitStruct.IsBufferable = MPU_ACCESS_BUFFERABLE;

  HAL_MPU_ConfigRegion(&MPU_InitStruct);

  /** Initializes and configures the Region and the memory to be protected
  */
  MPU_InitStruct.Number = MPU_REGION_NUMBER2;
  MPU_InitStruct.BaseAddress = 0x30000000;
  MPU_InitStruct.Size = MPU_REGION_SIZE_256KB;

  HAL_MPU_ConfigRegion(&MPU_InitStruct);

  /** Initializes and configures the Region and the memory to be protected
  */
  MPU_InitStruct.Number = MPU_REGION_NUMBER3;
  MPU_InitStruct.BaseAddress = 0x38000000;
  MPU_InitStruct.Size = MPU_REGION_SIZE_64KB;

  HAL_MPU_ConfigRegion(&MPU_InitStruct);

  /** Initializes and configures the Region and the memory to be protected
  */
  MPU_InitStruct.Number = MPU_REGION_NUMBER4;
  MPU_InitStruct.BaseAddress = 0x60000000;
  MPU_InitStruct.Size = MPU_REGION_SIZE_16MB;

  HAL_MPU_ConfigRegion(&MPU_InitStruct);
  /* Enables the MPU */
  HAL_MPU_Enable(MPU_PRIVILEGED_DEFAULT);

}

void HAL_TIM_PeriodElapsedCallback(TIM_HandleTypeDef *htim)
{
  if (htim->Instance == TIM14)
  {
    HAL_IncTick();
  }
}

void Error_Handler(void)
{
  /* USER CODE BEGIN Error_Handler_Debug */
	/* User can add his own implementation to report the HAL error return state */
	__disable_irq ();
	while ( 1 )
	{
	}
	/* USER CODE END Error_Handler_Debug */
}

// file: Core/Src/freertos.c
/* USER CODE BEGIN Header */
/**
  ******************************************************************************
  * File Name          : freertos.c
  * Description        : Code for freertos applications
  ******************************************************************************
  * @attention
  *
  * Copyright (c) 2026 STMicroelectronics.
  * All rights reserved.
  *
  * This software is licensed under terms that can be found in the LICENSE file
  * in the root directory of this software component.
  * If no LICENSE file comes with this software, it is provided AS-IS.
  *
  ******************************************************************************
  */
/* USER CODE END Header */

#include "FreeRTOS.h"
#include "task.h"
#include "main.h"
#include "cmsis_os.h"

/* USER CODE BEGIN Includes */
#include "google_cloud.h"
#include "fatfs.h"
#include "_debug.h"
#include "sd_card.h"
#include "tim.h"
#include "esp32wroom.h"
#include "timer.h"
#include "LCD_PortH7.h"
#include "network_start.h"
/* USER CODE END Includes */

/* USER CODE BEGIN PD */
/* Google Apps Script transport: GOOGLE_CLOUD_ETHERNET, GOOGLE_CLOUD_WIFI or GOOGLE_CLOUD_OFF. */
#define GOOGLE_CLOUD_TRANSPORT GOOGLE_CLOUD_OFF

/* USER CODE END PD */

/* USER CODE BEGIN Variables */
const int googleCloudTransport = GOOGLE_CLOUD_TRANSPORT;
 uint8_t ucHeap[ configTOTAL_HEAP_SIZE ] __attribute__ ((section(".sdram")));
/* USER CODE END Variables */
osThreadId defaultTaskHandle;

void StartDefaultTask(void const * argument);

extern void MX_LWIP_Init(void);
void MX_FREERTOS_Init(void); /* (MISRA C 2004 rule 8.1) */

/* GetIdleTaskMemory prototype (linked to static allocation support) */
void vApplicationGetIdleTaskMemory( StaticTask_t **ppxIdleTaskTCBBuffer, StackType_t **ppxIdleTaskStackBuffer, uint32_t *pulIdleTaskStackSize );

/* GetTimerTaskMemory prototype (linked to static allocation support) */
void vApplicationGetTimerTaskMemory( StaticTask_t **ppxTimerTaskTCBBuffer, StackType_t **ppxTimerTaskStackBuffer, uint32_t *pulTimerTaskStackSize );

/* Hook prototypes */
void vApplicationIdleHook(void);
void vApplicationTickHook(void);

/* USER CODE BEGIN 2 */
__weak void vApplicationIdleHook ( void )
{
	/* vApplicationIdleHook() will only be called if configUSE_IDLE_HOOK is set
   to 1 in FreeRTOSConfig.h. It will be called on each iteration of the idle
   task. It is essential that code added to this hook function never attempts
   to block in any way (for example, call xQueueReceive() with a block time
   specified, or call vTaskDelay()). If the application makes use of the
   vTaskDelete() API function (as this demo application does) then it is also
   important that vApplicationIdleHook() is permitted to return to its calling
   function, because it is the responsibility of the idle task to clean up
   memory allocated by the kernel to any task that has since been deleted. */
}
/* USER CODE END 2 */

/* USER CODE BEGIN 3 */
__weak void vApplicationTickHook ( void )
{
	/* This function will be called by each tick interrupt if
   configUSE_TICK_HOOK is set to 1 in FreeRTOSConfig.h. User code can be
   added here, but the tick hook is called from an interrupt context, so
   code must not attempt to block, and only the interrupt safe FreeRTOS API
   functions can be used (those that end in FromISR()). */
}
/* USER CODE END 3 */

/* USER CODE BEGIN GET_IDLE_TASK_MEMORY */
static StaticTask_t xIdleTaskTCBBuffer;
static StackType_t xIdleStack[configMINIMAL_STACK_SIZE];

void vApplicationGetIdleTaskMemory ( StaticTask_t **ppxIdleTaskTCBBuffer, StackType_t **ppxIdleTaskStackBuffer, uint32_t *pulIdleTaskStackSize )
{
	*ppxIdleTaskTCBBuffer = &xIdleTaskTCBBuffer;
	*ppxIdleTaskStackBuffer = &xIdleStack[0];
	*pulIdleTaskStackSize = configMINIMAL_STACK_SIZE;
	/* place for user code */
}
/* USER CODE END GET_IDLE_TASK_MEMORY */

/* USER CODE BEGIN GET_TIMER_TASK_MEMORY */
static StaticTask_t xTimerTaskTCBBuffer;
static StackType_t xTimerStack[configTIMER_TASK_STACK_DEPTH];

void vApplicationGetTimerTaskMemory ( StaticTask_t **ppxTimerTaskTCBBuffer, StackType_t **ppxTimerTaskStackBuffer, uint32_t *pulTimerTaskStackSize )
{
	*ppxTimerTaskTCBBuffer = &xTimerTaskTCBBuffer;
	*ppxTimerTaskStackBuffer = &xTimerStack[0];
	*pulTimerTaskStackSize = configTIMER_TASK_STACK_DEPTH;
	/* place for user code */
}
/* USER CODE END GET_TIMER_TASK_MEMORY */

void MX_FREERTOS_Init(void) {

  /* Create the thread(s) */
  /* definition and creation of defaultTask */
  osThreadDef(defaultTask, StartDefaultTask, osPriorityNormal, 0, 2048);
  defaultTaskHandle = osThreadCreate(osThread(defaultTask), NULL);

}

/* USER CODE BEGIN Header_StartDefaultTask */
/**
  * @brief  Function implementing the defaultTask thread.
  * @param  argument: Not used
  * @retval None
  */

//ALIGN_32BYTES(static char buff[200*1024]);
/* USER CODE END Header_StartDefaultTask */
void StartDefaultTask(void const * argument)
{
  /* USER CODE BEGIN StartDefaultTask */
	InitAllMutex ();

	Dbg ( 1, "\r\nHello Tu nowy STM32H753BIT6 Rafal Markielowski 123456789 " );
	/* Allow the SD card and touch controller power rails to settle. */
	osDelay ( 500 );
	MX_FATFS_Init ();
	DEBUG_Init ();
	/* LCD font diagnostics already use the queued logger during startup. */
	CreateLogTask ();
	if ( !LCD_H7_Start () )
		Dbg ( 1, "\r\nLCD H7 startup failed" );

	osDelay ( 1000 );
	//	SDCARD_WriteReadTest("aaa.htm","test.htm",buff,sizeof(buff));

	osDelay ( 500 );
	//CreateWifiTask ();
	NetworkStartEthernet ();

	/* Infinite loop */
	for ( ;; )
	{
		// Dbg(1,"i");
		osDelay ( 500 );
	}
	/* USER CODE END StartDefaultTask */
}
